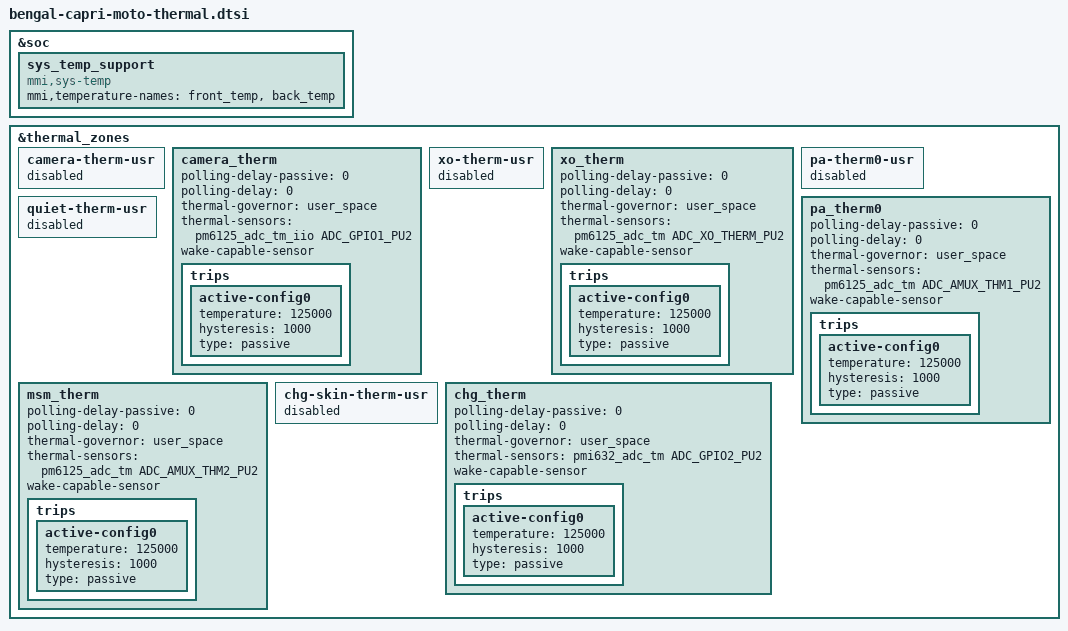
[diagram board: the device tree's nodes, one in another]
#include <dt-bindings/gpio/gpio.h>
#include <dt-bindings/iio/qcom,spmi-vadc.h>
#include <dt-bindings/input/input.h>

&soc {
        sys_temp_support {
                compatible = "mmi,sys-temp";
                mmi,temperature-names = "front_temp",
                        "back_temp";
                status = "ok";
        };
};

&thermal_zones {
	camera-therm-usr {
                status = "disabled";
        };
	
	camera_therm {
                polling-delay-passive = <0>;
                polling-delay = <0>;
                thermal-governor = "user_space";
                thermal-sensors = <&pm6125_adc_tm_iio ADC_GPIO1_PU2>;
                wake-capable-sensor;
                trips {
                        active-config0 {
                                temperature = <125000>;
                                hysteresis = <1000>;
                                type = "passive";
                        };
                };
        };

        xo-therm-usr {
		status = "disabled";
	};

	xo_therm {
                polling-delay-passive = <0>;
                polling-delay = <0>;
                thermal-governor = "user_space";
                thermal-sensors = <&pm6125_adc_tm ADC_XO_THERM_PU2>;
                wake-capable-sensor;
                trips {
                        active-config0 {
                                temperature = <125000>;
                                hysteresis = <1000>;
                                type = "passive";
                        };
                };
        };

	pa-therm0-usr {
		status = "disabled";
	};

	pa_therm0 {
                polling-delay-passive = <0>;
                polling-delay = <0>;
                thermal-governor = "user_space";
                thermal-sensors = <&pm6125_adc_tm ADC_AMUX_THM1_PU2>;
                wake-capable-sensor;
                trips {
                        active-config0 {
                                temperature = <125000>;
                                hysteresis = <1000>;
                                type = "passive";
                        };
                };
        };

	quiet-therm-usr {
		status = "disabled";
	};

	msm_therm {
                polling-delay-passive = <0>;
                polling-delay = <0>;
                thermal-governor = "user_space";
                thermal-sensors = <&pm6125_adc_tm ADC_AMUX_THM2_PU2>;
                wake-capable-sensor;
                trips {
                        active-config0 {
                                temperature = <125000>;
                                hysteresis = <1000>;
                                type = "passive";
                        };
                };
        };

	chg-skin-therm-usr {
		status = "disabled";
	};

	chg_therm {
                polling-delay-passive = <0>;
                polling-delay = <0>;
                thermal-governor = "user_space";
                thermal-sensors = <&pmi632_adc_tm ADC_GPIO2_PU2>;
                wake-capable-sensor;
                trips {
                        active-config0 {
                                temperature = <125000>;
                                hysteresis = <1000>;
                                type = "passive";
                        };
                };
        };
};

